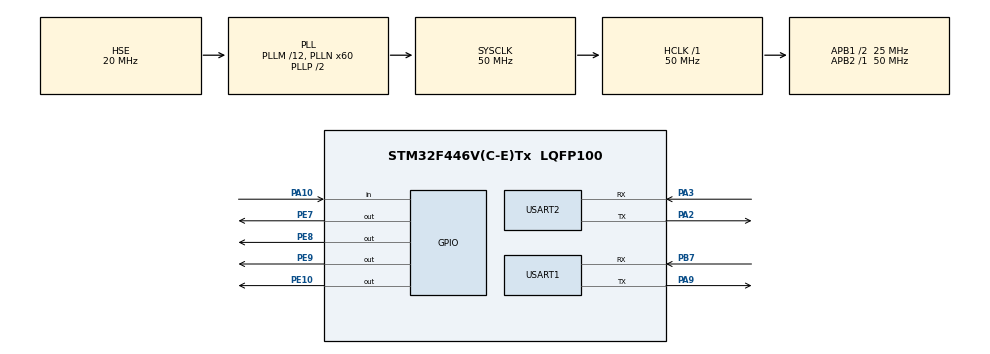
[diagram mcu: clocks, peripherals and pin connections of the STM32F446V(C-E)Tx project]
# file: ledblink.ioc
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Mcu.Family=STM32F4
Mcu.Name=STM32F446V(C-E)Tx
Mcu.Package=LQFP100
NVIC.PriorityGroup=NVIC_PRIORITYGROUP_4
PA10.Signal=GPIO_Input
PA2.Mode=Asynchronous
PA2.Signal=USART2_TX
PA3.Mode=Asynchronous
PA3.Signal=USART2_RX
PA9.Mode=Asynchronous
PA9.Signal=USART1_TX
PB7.Mode=Asynchronous
PB7.Signal=USART1_RX
PC14-OSC32_IN.Mode=LSE-External-Oscillator
PC14-OSC32_IN.Signal=RCC_OSC32_IN
PC15-OSC32_OUT.Mode=LSE-External-Oscillator
PC15-OSC32_OUT.Signal=RCC_OSC32_OUT
PE10.Signal=GPIO_Output
PE7.Signal=GPIO_Output
PE8.Signal=GPIO_Output
PE9.Signal=GPIO_Output
PH0-OSC_IN.Mode=HSE-External-Oscillator
PH0-OSC_IN.Signal=RCC_OSC_IN
PH1-OSC_OUT.Mode=HSE-External-Oscillator
PH1-OSC_OUT.Signal=RCC_OSC_OUT
ProjectManager.HeapSize=0x200
ProjectManager.StackSize=0x400
ProjectManager.TargetToolchain=STM32CubeIDE
RCC.AHBFreq_Value=50000000
RCC.APB1CLKDivider=RCC_HCLK_DIV2
RCC.APB1Freq_Value=25000000
RCC.APB1TimFreq_Value=50000000
RCC.APB2Freq_Value=50000000
RCC.APB2TimFreq_Value=50000000
RCC.CortexFreq_Value=50000000
RCC.HCLKFreq_Value=50000000
RCC.HSE_VALUE=20000000
RCC.PLLM=12
RCC.PLLN=60
RCC.PLLSourceVirtual=RCC_PLLSOURCE_HSE
RCC.SYSCLKFreq_VALUE=50000000
RCC.SYSCLKSource=RCC_SYSCLKSOURCE_PLLCLK
RCC.USBFreq_Value=50000000
RCC.VCOOutputFreq_Value=100000000
USART1.VirtualMode=VM_ASYNC
USART2.VirtualMode=VM_ASYNC
board=custom

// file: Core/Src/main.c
/* USER CODE BEGIN Header */
/**
  ******************************************************************************
  * @file           : main.c
  * @brief          : Main program body
  ******************************************************************************
  * @attention
  *
  * Copyright (c) 2024 STMicroelectronics.
  * All rights reserved.
  *
  * This software is licensed under terms that can be found in the LICENSE file
  * in the root directory of this software component.
  * If no LICENSE file comes with this software, it is provided AS-IS.
  *
  ******************************************************************************
  */
/* USER CODE END Header */
#include "main.h"

UART_HandleTypeDef huart1;
UART_HandleTypeDef huart2;

void SystemClock_Config(void);
static void MX_GPIO_Init(void);
static void MX_USART1_UART_Init(void);
static void MX_USART2_UART_Init(void);

int main(void)
{

  /* MCU Configuration--------------------------------------------------------*/

  /* Reset of all peripherals, Initializes the Flash interface and the Systick. */
  HAL_Init();

  /* Configure the system clock */
  SystemClock_Config();

  /* Initialize all configured peripherals */
  MX_GPIO_Init();
  MX_USART1_UART_Init();
  MX_USART2_UART_Init();

  /* Infinite loop */
  while (1)
  {

    /* USER CODE BEGIN 3 */

		  HAL_GPIO_WritePin(GPIOE, GPIO_PIN_10,GPIO_PIN_SET);// SET THE PN10 IN PORT E AS HIGH
		  HAL_Delay(1000);// PUT A DELAY OF 1s
		  HAL_GPIO_WritePin(GPIOE, GPIO_PIN_10,GPIO_PIN_RESET);// SET THE PN10 IN PORT E AS LOW
		  HAL_Delay(1000);// PUT A DELAY OF 1s

  }
  /* USER CODE END 3 */
}

void SystemClock_Config(void)
{
  RCC_OscInitTypeDef RCC_OscInitStruct = {0};
  RCC_ClkInitTypeDef RCC_ClkInitStruct = {0};

  /** Configure the main internal regulator output voltage
  */
  __HAL_RCC_PWR_CLK_ENABLE();
  __HAL_PWR_VOLTAGESCALING_CONFIG(PWR_REGULATOR_VOLTAGE_SCALE3);

  /** Initializes the RCC Oscillators according to the specified parameters
  * in the RCC_OscInitTypeDef structure.
  */
  RCC_OscInitStruct.OscillatorType = RCC_OSCILLATORTYPE_HSE;
  RCC_OscInitStruct.HSEState = RCC_HSE_ON;
  RCC_OscInitStruct.PLL.PLLState = RCC_PLL_ON;
  RCC_OscInitStruct.PLL.PLLSource = RCC_PLLSOURCE_HSE;
  RCC_OscInitStruct.PLL.PLLM = 12;
  RCC_OscInitStruct.PLL.PLLN = 60;
  RCC_OscInitStruct.PLL.PLLP = RCC_PLLP_DIV2;
  RCC_OscInitStruct.PLL.PLLQ = 2;
  RCC_OscInitStruct.PLL.PLLR = 2;
  if (HAL_RCC_OscConfig(&RCC_OscInitStruct) != HAL_OK)
  {
    Error_Handler();
  }

  /** Initializes the CPU, AHB and APB buses clocks
  */
  RCC_ClkInitStruct.ClockType = RCC_CLOCKTYPE_HCLK|RCC_CLOCKTYPE_SYSCLK
                              |RCC_CLOCKTYPE_PCLK1|RCC_CLOCKTYPE_PCLK2;
  RCC_ClkInitStruct.SYSCLKSource = RCC_SYSCLKSOURCE_PLLCLK;
  RCC_ClkInitStruct.AHBCLKDivider = RCC_SYSCLK_DIV1;
  RCC_ClkInitStruct.APB1CLKDivider = RCC_HCLK_DIV2;
  RCC_ClkInitStruct.APB2CLKDivider = RCC_HCLK_DIV1;

  if (HAL_RCC_ClockConfig(&RCC_ClkInitStruct, FLASH_LATENCY_1) != HAL_OK)
  {
    Error_Handler();
  }
}

static void MX_USART1_UART_Init(void)
{

  huart1.Instance = USART1;
  huart1.Init.BaudRate = 115200;
  huart1.Init.WordLength = UART_WORDLENGTH_8B;
  huart1.Init.StopBits = UART_STOPBITS_1;
  huart1.Init.Parity = UART_PARITY_NONE;
  huart1.Init.Mode = UART_MODE_TX_RX;
  huart1.Init.HwFlowCtl = UART_HWCONTROL_NONE;
  huart1.Init.OverSampling = UART_OVERSAMPLING_16;
  if (HAL_UART_Init(&huart1) != HAL_OK)
  {
    Error_Handler();
  }

}

static void MX_USART2_UART_Init(void)
{

  huart2.Instance = USART2;
  huart2.Init.BaudRate = 115200;
  huart2.Init.WordLength = UART_WORDLENGTH_8B;
  huart2.Init.StopBits = UART_STOPBITS_1;
  huart2.Init.Parity = UART_PARITY_NONE;
  huart2.Init.Mode = UART_MODE_TX_RX;
  huart2.Init.HwFlowCtl = UART_HWCONTROL_NONE;
  huart2.Init.OverSampling = UART_OVERSAMPLING_16;
  if (HAL_UART_Init(&huart2) != HAL_OK)
  {
    Error_Handler();
  }

}

static void MX_GPIO_Init(void)
{
  GPIO_InitTypeDef GPIO_InitStruct = {0};

  /* GPIO Ports Clock Enable */
  __HAL_RCC_GPIOC_CLK_ENABLE();
  __HAL_RCC_GPIOH_CLK_ENABLE();
  __HAL_RCC_GPIOA_CLK_ENABLE();
  __HAL_RCC_GPIOE_CLK_ENABLE();
  __HAL_RCC_GPIOB_CLK_ENABLE();

  /*Configure GPIO pin Output Level */
  HAL_GPIO_WritePin(GPIOE, GPIO_PIN_7|GPIO_PIN_8|GPIO_PIN_9|GPIO_PIN_10, GPIO_PIN_RESET);

  /*Configure GPIO pins : PE7 PE8 PE9 PE10 */
  GPIO_InitStruct.Pin = GPIO_PIN_7|GPIO_PIN_8|GPIO_PIN_9|GPIO_PIN_10;
  GPIO_InitStruct.Mode = GPIO_MODE_OUTPUT_PP;
  GPIO_InitStruct.Pull = GPIO_NOPULL;
  GPIO_InitStruct.Speed = GPIO_SPEED_FREQ_LOW;
  HAL_GPIO_Init(GPIOE, &GPIO_InitStruct);

  /*Configure GPIO pin : PA10 */
  GPIO_InitStruct.Pin = GPIO_PIN_10;
  GPIO_InitStruct.Mode = GPIO_MODE_INPUT;
  GPIO_InitStruct.Pull = GPIO_NOPULL;
  HAL_GPIO_Init(GPIOA, &GPIO_InitStruct);

}

void Error_Handler(void)
{
  __disable_irq();
  while (1)
  {
  }
}
